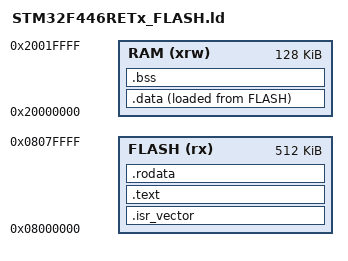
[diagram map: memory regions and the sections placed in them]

ENTRY(Reset_Handler)


_estack = ORIGIN(RAM) + LENGTH(RAM);

MEMORY {

    FLASH (rx) : ORIGIN = 0x08000000, LENGTH = 512k

    RAM (xrw) : ORIGIN = 0x20000000, LENGTH = 128k
}

SECTIONS {
    .isr_vector : {
        . = ALIGN(4);
        KEEP(*(.isr_vector))
        . = ALIGN(4);
    } >FLASH

    .text : {
        . = ALIGN(4);
        *(.text)
        *(.text*)
        . = ALIGN(4);
    } >FLASH

    .rodata : {
        . = ALIGN(4);
        *(.rodata)
        *(.rodata*)
        . = ALIGN(4);
    } >FLASH

    _sidata = LOADADDR(.data);

    .data : {
        . = ALIGN(4);
        _sdata = .;
        *(.data)
        *(.data*)
        . = ALIGN(4);
        _edata = .;
    } >RAM AT>FLASH

    .bss : {
        . = ALIGN(4);
        _sbss = .;
        *(.bss)
        *(.bss*)
        *(COMMON)
        . = ALIGN(4);
        _ebss = .;
    } >RAM

    /DISCARD/ :
    {
        libc.a ( * )
        libm.a ( * )
        libgcc.a ( * )
    }
}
